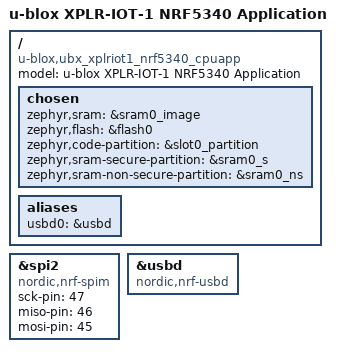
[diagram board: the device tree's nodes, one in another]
/*
 * u-blox XPLR-IOT-1 board configuration
 * Copyright (c) 2022 u-blox AG
 *
 * SPDX-License-Identifier: Apache-2.0
 */
 
/dts-v1/;
#include <nordic/nrf5340_cpuapp_qkaa.dtsi>
#include "nrf5340_cpuapp_common.dts"

/ {
	model = "u-blox XPLR-IOT-1 NRF5340 Application";
	compatible = "u-blox,ubx_xplriot1_nrf5340_cpuapp";

	chosen {
		zephyr,sram = &sram0_image;
		zephyr,flash = &flash0;
		zephyr,code-partition = &slot0_partition;
		zephyr,sram-secure-partition = &sram0_s;
		zephyr,sram-non-secure-partition = &sram0_ns;
	};

	aliases {
		usbd0 = &usbd;
	};
};

&spi2 {
	compatible = "nordic,nrf-spim";
	status = "okay";
	sck-pin = <47>;
	miso-pin = <46>;
	mosi-pin = <45>;
};

&usbd {
	compatible = "nordic,nrf-usbd";
	status = "okay";
};
